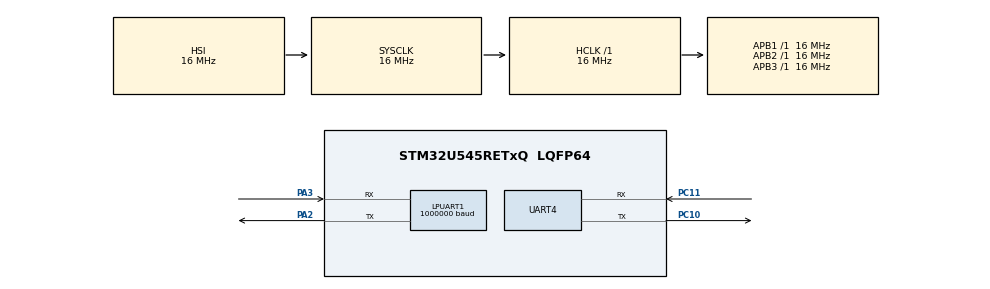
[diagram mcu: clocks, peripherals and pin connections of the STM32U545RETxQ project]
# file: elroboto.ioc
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CORTEX_M33_NS.userName=CORTEX_M33
LPUART1.BaudRate=1000000
LPUART1.FifoMode=FIFOMODE_ENABLE
Mcu.Family=STM32U5
Mcu.Name=STM32U545RETxQ
Mcu.Package=LQFP64
NUCLEO-U545RE-Q.BUTTON=1
NUCLEO-U545RE-Q.VCP=true
NVIC.EXTI13_IRQn=true\:0\:0\:false\:false\:true\:false\:true\:true
NVIC.PriorityGroup=NVIC_PRIORITYGROUP_4
NVIC.UART4_IRQn=true\:0\:0\:false\:false\:true\:true\:true\:true
PA2.Mode=Asynchronous
PA2.Signal=LPUART1_TX
PA3.Mode=Asynchronous
PA3.Signal=LPUART1_RX
PC10.Mode=Asynchronous
PC10.Signal=UART4_TX
PC11.Mode=Asynchronous
PC11.Signal=UART4_RX
PWR.PowerMode=PWR_SMPS_SUPPLY
ProjectManager.HeapSize=0x200
ProjectManager.StackSize=0x400
ProjectManager.TargetToolchain=CMake
RCC.ADCFreq_Value=16000000
RCC.AHBFreq_Value=16000000
RCC.APB1Freq_Value=16000000
RCC.APB1TimFreq_Value=16000000
RCC.APB2Freq_Value=16000000
RCC.APB2TimFreq_Value=16000000
RCC.APB3Freq_Value=16000000
RCC.CortexFreq_Value=16000000
RCC.DACCLockSelectionVirtual=RCC_DAC1CLKSOURCE_LSI
RCC.DACCLockSelectionVirtualString=RCC_DAC1CLKSOURCE_LSI
RCC.EPOD_VALUE=16000000
RCC.HCLKFreq_Value=16000000
RCC.HSE_VALUE=16000000
RCC.HSI48_VALUE=48000000
RCC.HSI_VALUE=16000000
RCC.LPUART1CLockSelectionVirtual=RCC_LPUART1CLKSOURCE_HSI
RCC.LSE_VALUE=32768
RCC.LSIDIV_VALUE=32000
RCC.MSI_VALUE=4000000
RCC.PLLSourceVirtual=RCC_PLLSOURCE_HSI
RCC.SYSCLKFreq_VALUE=16000000
RCC.SYSCLKSource=RCC_SYSCLKSOURCE_HSI
RCC.USART3CLockSelectionVirtual=RCC_USART3CLKSOURCE_HSI
RCC.USBFreq_Value=48000000
RCC.VCOOutputFreq_Value=2064000000
VP_ICACHE_VS_ICACHE.Mode=DirectMappedCache
VP_LPBAMQUEUE_VS_QUEUE.Mode=QUEUEMODE
VP_MEMORYMAP_VS_MEMORYMAP.Mode=CurAppReg
VP_NUCLEO-U545RE-Q_VS_BSP_COMMON.Mode=COMMON
VP_PWR_VS_LPOM.Mode=PowerOptimisation
VP_PWR_VS_SECSignals.Mode=Security/Privilege
board=NUCLEO-U545RE-Q

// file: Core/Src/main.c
/* USER CODE BEGIN Header */
/**
  ******************************************************************************
  * @file           : main.c
  * @brief          : Main program body
  ******************************************************************************
  * @attention
  *
  * Copyright (c) 2026 STMicroelectronics.
  * All rights reserved.
  *
  * This software is licensed under terms that can be found in the LICENSE file
  * in the root directory of this software component.
  * If no LICENSE file comes with this software, it is provided AS-IS.
  *
  ******************************************************************************
  */
/* USER CODE END Header */
#include "main.h"

/* USER CODE BEGIN Includes */
#include "app.h"
/* USER CODE END Includes */

COM_InitTypeDef BspCOMInit;

UART_HandleTypeDef hlpuart1;
UART_HandleTypeDef huart4;

void SystemClock_Config(void);
static void SystemPower_Config(void);
static void MX_GPIO_Init(void);
static void MX_ICACHE_Init(void);
static void MX_LPUART1_UART_Init(void);
static void MX_UART4_Init(void);

int main(void)
{

  /* MCU Configuration--------------------------------------------------------*/

  /* Reset of all peripherals, Initializes the Flash interface and the Systick. */
  HAL_Init();

  /* Configure the System Power */
  SystemPower_Config();

  /* Configure the system clock */
  SystemClock_Config();

  /* Initialize all configured peripherals */
  MX_GPIO_Init();
  MX_ICACHE_Init();
  MX_LPUART1_UART_Init();
  MX_UART4_Init();

  /* Initialize USER push-button, will be used to trigger an interrupt each time it's pressed.*/
  BSP_PB_Init(BUTTON_USER, BUTTON_MODE_EXTI);

  /* Initialize COM1 port (115200, 8 bits (7-bit data + 1 stop bit), no parity */
  BspCOMInit.BaudRate   = 115200;
  BspCOMInit.WordLength = COM_WORDLENGTH_8B;
  BspCOMInit.StopBits   = COM_STOPBITS_1;
  BspCOMInit.Parity     = COM_PARITY_NONE;
  BspCOMInit.HwFlowCtl  = COM_HWCONTROL_NONE;
  if (BSP_COM_Init(COM1, &BspCOMInit) != BSP_ERROR_NONE)
  {
    Error_Handler();
  }

  /* Infinite loop */
  /* USER CODE BEGIN WHILE */
  App_Init(&hlpuart1, &huart4);

  while (1)
  {
    App_Process(HAL_GetTick());

    /* USER CODE END WHILE */

  }
}

void SystemClock_Config(void)
{
  RCC_OscInitTypeDef RCC_OscInitStruct = {0};
  RCC_ClkInitTypeDef RCC_ClkInitStruct = {0};

  /** Configure the main internal regulator output voltage
  */
  if (HAL_PWREx_ControlVoltageScaling(PWR_REGULATOR_VOLTAGE_SCALE4) != HAL_OK)
  {
    Error_Handler();
  }

  /** Initializes the CPU, AHB and APB buses clocks
  */
  RCC_OscInitStruct.OscillatorType = RCC_OSCILLATORTYPE_HSI;
  RCC_OscInitStruct.HSIState = RCC_HSI_ON;
  RCC_OscInitStruct.HSICalibrationValue = RCC_HSICALIBRATION_DEFAULT;
  RCC_OscInitStruct.PLL.PLLState = RCC_PLL_NONE;
  if (HAL_RCC_OscConfig(&RCC_OscInitStruct) != HAL_OK)
  {
    Error_Handler();
  }

  /** Initializes the CPU, AHB and APB buses clocks
  */
  RCC_ClkInitStruct.ClockType = RCC_CLOCKTYPE_HCLK|RCC_CLOCKTYPE_SYSCLK
                              |RCC_CLOCKTYPE_PCLK1|RCC_CLOCKTYPE_PCLK2
                              |RCC_CLOCKTYPE_PCLK3;
  RCC_ClkInitStruct.SYSCLKSource = RCC_SYSCLKSOURCE_HSI;
  RCC_ClkInitStruct.AHBCLKDivider = RCC_SYSCLK_DIV1;
  RCC_ClkInitStruct.APB1CLKDivider = RCC_HCLK_DIV1;
  RCC_ClkInitStruct.APB2CLKDivider = RCC_HCLK_DIV1;
  RCC_ClkInitStruct.APB3CLKDivider = RCC_HCLK_DIV1;

  if (HAL_RCC_ClockConfig(&RCC_ClkInitStruct, FLASH_LATENCY_1) != HAL_OK)
  {
    Error_Handler();
  }
}

/**
  * @brief Power Configuration
  * @retval None
  */
static void SystemPower_Config(void)
{

  /*
   * Switch to SMPS regulator instead of LDO
   */
  if (HAL_PWREx_ConfigSupply(PWR_SMPS_SUPPLY) != HAL_OK)
  {
    Error_Handler();
  }
}

static void MX_ICACHE_Init(void)
{

  /** Enable instruction cache in 1-way (direct mapped cache)
  */
  if (HAL_ICACHE_ConfigAssociativityMode(ICACHE_1WAY) != HAL_OK)
  {
    Error_Handler();
  }
  if (HAL_ICACHE_Enable() != HAL_OK)
  {
    Error_Handler();
  }

}

static void MX_LPUART1_UART_Init(void)
{

  hlpuart1.Instance = LPUART1;
  hlpuart1.Init.BaudRate = 1000000;
  hlpuart1.Init.WordLength = UART_WORDLENGTH_8B;
  hlpuart1.Init.StopBits = UART_STOPBITS_1;
  hlpuart1.Init.Parity = UART_PARITY_NONE;
  hlpuart1.Init.Mode = UART_MODE_TX_RX;
  hlpuart1.Init.HwFlowCtl = UART_HWCONTROL_NONE;
  hlpuart1.Init.OneBitSampling = UART_ONE_BIT_SAMPLE_DISABLE;
  hlpuart1.Init.ClockPrescaler = UART_PRESCALER_DIV1;
  hlpuart1.AdvancedInit.AdvFeatureInit = UART_ADVFEATURE_NO_INIT;
  hlpuart1.FifoMode = UART_FIFOMODE_DISABLE;
  if (HAL_UART_Init(&hlpuart1) != HAL_OK)
  {
    Error_Handler();
  }
  if (HAL_UARTEx_SetTxFifoThreshold(&hlpuart1, UART_TXFIFO_THRESHOLD_1_8) != HAL_OK)
  {
    Error_Handler();
  }
  if (HAL_UARTEx_SetRxFifoThreshold(&hlpuart1, UART_RXFIFO_THRESHOLD_1_8) != HAL_OK)
  {
    Error_Handler();
  }
  if (HAL_UARTEx_DisableFifoMode(&hlpuart1) != HAL_OK)
  {
    Error_Handler();
  }
  /* USER CODE BEGIN LPUART1_Init 2 */

  if (HAL_UARTEx_SetRxFifoThreshold(&hlpuart1, UART_RXFIFO_THRESHOLD_1_8) != HAL_OK)
  {
    Error_Handler();
  }
  if (HAL_UARTEx_EnableFifoMode(&hlpuart1) != HAL_OK)
  {
    Error_Handler();
  }

  /* USER CODE END LPUART1_Init 2 */

}

static void MX_UART4_Init(void)
{

  huart4.Instance = UART4;
  huart4.Init.BaudRate = 115200;
  huart4.Init.WordLength = UART_WORDLENGTH_8B;
  huart4.Init.StopBits = UART_STOPBITS_1;
  huart4.Init.Parity = UART_PARITY_NONE;
  huart4.Init.Mode = UART_MODE_TX_RX;
  huart4.Init.HwFlowCtl = UART_HWCONTROL_NONE;
  huart4.Init.OverSampling = UART_OVERSAMPLING_16;
  huart4.Init.OneBitSampling = UART_ONE_BIT_SAMPLE_DISABLE;
  huart4.Init.ClockPrescaler = UART_PRESCALER_DIV1;
  huart4.AdvancedInit.AdvFeatureInit = UART_ADVFEATURE_NO_INIT;
  if (HAL_UART_Init(&huart4) != HAL_OK)
  {
    Error_Handler();
  }
  if (HAL_UARTEx_SetTxFifoThreshold(&huart4, UART_TXFIFO_THRESHOLD_1_8) != HAL_OK)
  {
    Error_Handler();
  }
  if (HAL_UARTEx_SetRxFifoThreshold(&huart4, UART_RXFIFO_THRESHOLD_1_8) != HAL_OK)
  {
    Error_Handler();
  }
  if (HAL_UARTEx_DisableFifoMode(&huart4) != HAL_OK)
  {
    Error_Handler();
  }

}

static void MX_GPIO_Init(void)
{

  /* GPIO Ports Clock Enable */
  __HAL_RCC_GPIOA_CLK_ENABLE();
  __HAL_RCC_GPIOC_CLK_ENABLE();

}

/* USER CODE BEGIN 4 */

void BSP_PB_Callback(Button_TypeDef Button)
{
  if (Button == BUTTON_USER)
  {
    App_OnButtonInterrupt();
  }
}

/* USER CODE END 4 */

void Error_Handler(void)
{
  __disable_irq();
  while (1)
  {
  }
}
